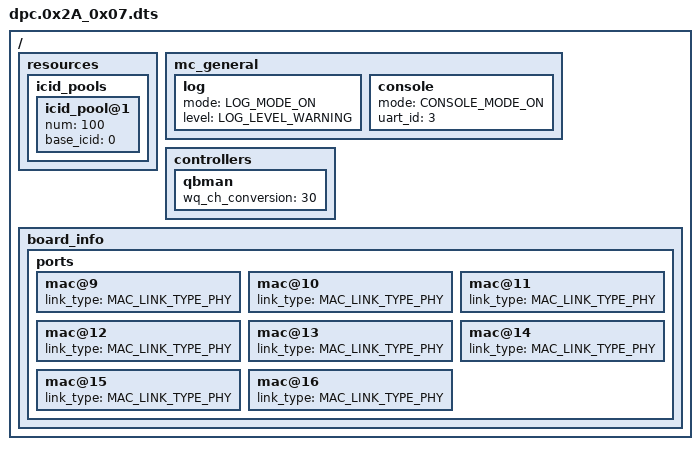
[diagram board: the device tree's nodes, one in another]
/*
 * Copyright 2016 Freescale Semiconductor, Inc.
 * Copyright 2017 NXP
 *
 * Redistribution and use in source and binary forms, with or without
 * modification, are permitted provided that the following conditions are met:
 *   * Redistributions of source code must retain the above copyright
 *     notice, this list of conditions and the following disclaimer.
 *   * Redistributions in binary form must reproduce the above copyright
 *     notice, this list of conditions and the following disclaimer in the
 *     documentation and/or other materials provided with the distribution.
 *   * Neither the name of the above-listed copyright holders nor the
 *     names of any contributors may be used to endorse or promote products
 *     derived from this software without specific prior written permission.
 *
 * THIS SOFTWARE IS PROVIDED BY THE COPYRIGHT HOLDERS AND CONTRIBUTORS "AS IS"
 * AND ANY EXPRESS OR IMPLIED WARRANTIES, INCLUDING, BUT NOT LIMITED TO, THE
 * IMPLIED WARRANTIES OF MERCHANTABILITY AND FITNESS FOR A PARTICULAR PURPOSE
 * ARE DISCLAIMED. IN NO EVENT SHALL THE COPYRIGHT HOLDERS OR CONTRIBUTORS BE
 * LIABLE FOR ANY DIRECT, INDIRECT, INCIDENTAL, SPECIAL, EXEMPLARY, OR
 * CONSEQUENTIAL DAMAGES (INCLUDING, BUT NOT LIMITED TO, PROCUREMENT OF
 * SUBSTITUTE GOODS OR SERVICES; LOSS OF USE, DATA, OR PROFITS; OR BUSINESS
 * INTERRUPTION) HOWEVER CAUSED AND ON ANY THEORY OF LIABILITY, WHETHER IN
 * CONTRACT, STRICT LIABILITY, OR TORT (INCLUDING NEGLIGENCE OR OTHERWISE)
 * ARISING IN ANY WAY OUT OF THE USE OF THIS SOFTWARE, EVEN IF ADVISED OF THE
 * POSSIBILITY OF SUCH DAMAGE.
 */

/*
 * This DPC showcases one Linux configuration for SerDes 0x2a_0x07.
 */

/dts-v1/;
/ {
	resources {
		icid_pools {
			icid_pool@1 {
				num = <100>;
				base_icid = <0>;
			};
		};
	};
	mc_general {
		log {
			mode = "LOG_MODE_ON";
			level = "LOG_LEVEL_WARNING";
		};
		console {
			mode = "CONSOLE_MODE_ON";
			uart_id = <3>;
		};
	};
	controllers {
		qbman {
			/* Transform 30 8-WQ channels into 120 2-WQ channels */
			wq_ch_conversion = <30>;
		};
	};
	board_info {
		ports {
			/* For QDS SerDes 0x2a_07: 8 SGMII ports.
			 * The 5 XFIs are probed as fixed-links which is the default
			 * in the DPC, so not representing those explicitly.
			 */
			mac@9 {
				link_type = "MAC_LINK_TYPE_PHY";
			};
			mac@10 {
				link_type = "MAC_LINK_TYPE_PHY";
			};
			mac@11 {
				link_type = "MAC_LINK_TYPE_PHY";
			};
			mac@12 {
				link_type = "MAC_LINK_TYPE_PHY";
			};
			mac@13 {
				link_type = "MAC_LINK_TYPE_PHY";
			};
			mac@14 {
				link_type = "MAC_LINK_TYPE_PHY";
			};
			mac@15 {
				link_type = "MAC_LINK_TYPE_PHY";
			};
			mac@16 {
				link_type = "MAC_LINK_TYPE_PHY";
			};
		};
	};
};
